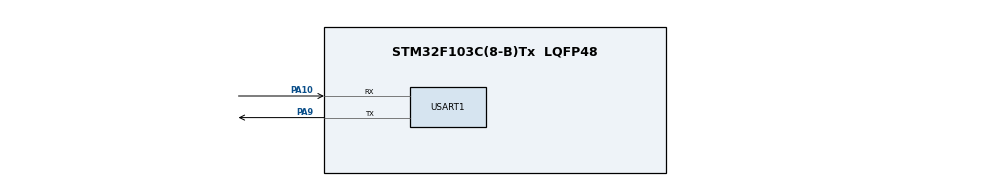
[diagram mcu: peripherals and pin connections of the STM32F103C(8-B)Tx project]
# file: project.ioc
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FREERTOS.Mutexes01=myMutex01,Dynamic,NULL,Available
FREERTOS.Tasks01=FastTask,24,128,StartFastTask,Default,NULL,Dynamic,NULL,NULL;MedTask,16,128,StartMedTask,Default,NULL,Dynamic,NULL,NULL;SlowTask,8,128,StartSlowTask,Default,NULL,Dynamic,NULL,NULL
FREERTOS.configTOTAL_HEAP_SIZE=8192
Mcu.Family=STM32F1
Mcu.Name=STM32F103C(8-B)Tx
Mcu.Package=LQFP48
NVIC.PriorityGroup=NVIC_PRIORITYGROUP_4
PA10.Mode=Asynchronous
PA10.Signal=USART1_RX
PA9.Mode=Asynchronous
PA9.Signal=USART1_TX
ProjectManager.HeapSize=0x200
ProjectManager.StackSize=0x400
ProjectManager.TargetToolchain=STM32CubeIDE
RCC.APB1Freq_Value=8000000
RCC.APB2Freq_Value=8000000
USART1.VirtualMode=VM_ASYNC
VP_FREERTOS_VS_CMSIS_V2.Mode=CMSIS_V2
VP_SYS_VS_ND.Mode=No_Debug
board=custom

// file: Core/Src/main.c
/* USER CODE BEGIN Header */
/**
  ******************************************************************************
  * @file           : main.c
  * @brief          : Main program body
  ******************************************************************************
  * @attention
  *
  * Copyright (c) 2026 STMicroelectronics.
  * All rights reserved.
  *
  * This software is licensed under terms that can be found in the LICENSE file
  * in the root directory of this software component.
  * If no LICENSE file comes with this software, it is provided AS-IS.
  *
  ******************************************************************************
  */
/* USER CODE END Header */
#include "main.h"
#include "cmsis_os.h"

/* USER CODE BEGIN Includes */
#include <stdio.h>      // vsnprintf
#include <stdarg.h>     // va_list, va_start, va_end
#include <string.h>     // strlen
/* USER CODE END Includes */

/* USER CODE BEGIN PD */
#define USE_MUTEX      1
#define LOG_BUF_SIZE   256
/* USER CODE END PD */

UART_HandleTypeDef huart1;

/* Definitions for FastTask */
osThreadId_t FastTaskHandle;
const osThreadAttr_t FastTask_attributes = {
  .name = "FastTask",
  .stack_size = 128 * 4,
  .priority = (osPriority_t) osPriorityNormal,
};
/* Definitions for MedTask */
osThreadId_t MedTaskHandle;
const osThreadAttr_t MedTask_attributes = {
  .name = "MedTask",
  .stack_size = 128 * 4,
  .priority = (osPriority_t) osPriorityBelowNormal,
};
/* Definitions for SlowTask */
osThreadId_t SlowTaskHandle;
const osThreadAttr_t SlowTask_attributes = {
  .name = "SlowTask",
  .stack_size = 128 * 4,
  .priority = (osPriority_t) osPriorityLow,
};
/* Definitions for myMutex01 */
osMutexId_t myMutex01Handle;
const osMutexAttr_t myMutex01_attributes = {
  .name = "myMutex01"
};

void SystemClock_Config(void);
static void MX_GPIO_Init(void);
static void MX_USART1_UART_Init(void);
void StartFastTask(void *argument);
void StartMedTask(void *argument);
void StartSlowTask(void *argument);

int main(void)
{

  /* MCU Configuration--------------------------------------------------------*/

  /* Reset of all peripherals, Initializes the Flash interface and the Systick. */
  HAL_Init();

  /* Configure the system clock */
  SystemClock_Config();

  /* Initialize all configured peripherals */
  MX_GPIO_Init();
  MX_USART1_UART_Init();
  /* USER CODE BEGIN 2 */
  {
      const char *banner =
#if USE_MUTEX
          "\r\n=== UART MUTEX DEMO — MUTEX ON  ===\r\n\r\n";
#else
          "\r\n=== UART MUTEX DEMO — MUTEX OFF (expect garbage) ===\r\n\r\n";
#endif
      HAL_UART_Transmit(&huart1, (uint8_t *)banner, strlen(banner), 200);
  }

  /* USER CODE END 2 */

  /* Init scheduler */
  osKernelInitialize();
  /* Create the mutex(es) */
  /* creation of myMutex01 */
  myMutex01Handle = osMutexNew(&myMutex01_attributes);

  /* Create the thread(s) */
  /* creation of FastTask */
  FastTaskHandle = osThreadNew(StartFastTask, NULL, &FastTask_attributes);

  /* creation of MedTask */
  MedTaskHandle = osThreadNew(StartMedTask, NULL, &MedTask_attributes);

  /* creation of SlowTask */
  SlowTaskHandle = osThreadNew(StartSlowTask, NULL, &SlowTask_attributes);

  /* USER CODE BEGIN RTOS_EVENTS */
  if (FastTaskHandle == NULL)
      HAL_UART_Transmit(&huart1, (uint8_t *)"FAST FAIL\r\n", 11, 100);
  else
      HAL_UART_Transmit(&huart1, (uint8_t *)"FAST OK\r\n", 9, 100);

  if (MedTaskHandle == NULL)
      HAL_UART_Transmit(&huart1, (uint8_t *)"MED FAIL\r\n", 11, 100);
  else
      HAL_UART_Transmit(&huart1, (uint8_t *)"MED OK\r\n", 9, 100);

  if (SlowTaskHandle == NULL)
      HAL_UART_Transmit(&huart1, (uint8_t *)"Slow FAIL\r\n", 11, 100);
  else
      HAL_UART_Transmit(&huart1, (uint8_t *)"Slow OK\r\n", 9, 100);
  /* add events, ... */
  /* USER CODE END RTOS_EVENTS */

  /* Start scheduler */
  osKernelStart();

  /* We should never get here as control is now taken by the scheduler */

  /* Infinite loop */
  while (1)
  {

  }
}

void SystemClock_Config(void)
{
  RCC_OscInitTypeDef RCC_OscInitStruct = {0};
  RCC_ClkInitTypeDef RCC_ClkInitStruct = {0};

  /** Initializes the RCC Oscillators according to the specified parameters
  * in the RCC_OscInitTypeDef structure.
  */
  RCC_OscInitStruct.OscillatorType = RCC_OSCILLATORTYPE_HSI;
  RCC_OscInitStruct.HSIState = RCC_HSI_ON;
  RCC_OscInitStruct.HSICalibrationValue = RCC_HSICALIBRATION_DEFAULT;
  RCC_OscInitStruct.PLL.PLLState = RCC_PLL_NONE;
  if (HAL_RCC_OscConfig(&RCC_OscInitStruct) != HAL_OK)
  {
    Error_Handler();
  }

  /** Initializes the CPU, AHB and APB buses clocks
  */
  RCC_ClkInitStruct.ClockType = RCC_CLOCKTYPE_HCLK|RCC_CLOCKTYPE_SYSCLK
                              |RCC_CLOCKTYPE_PCLK1|RCC_CLOCKTYPE_PCLK2;
  RCC_ClkInitStruct.SYSCLKSource = RCC_SYSCLKSOURCE_HSI;
  RCC_ClkInitStruct.AHBCLKDivider = RCC_SYSCLK_DIV1;
  RCC_ClkInitStruct.APB1CLKDivider = RCC_HCLK_DIV1;
  RCC_ClkInitStruct.APB2CLKDivider = RCC_HCLK_DIV1;

  if (HAL_RCC_ClockConfig(&RCC_ClkInitStruct, FLASH_LATENCY_0) != HAL_OK)
  {
    Error_Handler();
  }
}

static void MX_USART1_UART_Init(void)
{

  huart1.Instance = USART1;
  huart1.Init.BaudRate = 115200;
  huart1.Init.WordLength = UART_WORDLENGTH_8B;
  huart1.Init.StopBits = UART_STOPBITS_1;
  huart1.Init.Parity = UART_PARITY_NONE;
  huart1.Init.Mode = UART_MODE_TX_RX;
  huart1.Init.HwFlowCtl = UART_HWCONTROL_NONE;
  huart1.Init.OverSampling = UART_OVERSAMPLING_16;
  if (HAL_UART_Init(&huart1) != HAL_OK)
  {
    Error_Handler();
  }

}

static void MX_GPIO_Init(void)
{

  /* GPIO Ports Clock Enable */
  __HAL_RCC_GPIOA_CLK_ENABLE();

}

void StartFastTask(void *argument)
{
  /* USER CODE BEGIN 5 */
  /* Infinite loop */
	(void)argument;

	for(;;){
        HAL_UART_Transmit(&huart1, (uint8_t*)"High task waiting for mutex...\r\n",
                          33, HAL_MAX_DELAY);

        // Take mutex (blocks if held by Low task)
        osMutexAcquire(myMutex01Handle, osWaitForever);

        HAL_UART_Transmit(&huart1, (uint8_t*)"High task got mutex!\r\n", 24, HAL_MAX_DELAY);

        osMutexRelease(myMutex01Handle); // Release mutex
        osDelay(200);
	}
  /* USER CODE END 5 */
}

void StartMedTask(void *argument)
{
  /* USER CODE BEGIN StartMedTask */

  (void)argument;

  /* Infinite loop */
  for(;;)
  {

      HAL_UART_Transmit(&huart1, (uint8_t*)"Med task running\r\n", 18, HAL_MAX_DELAY);

      // Busy loop to simulate CPU work
      for (volatile int i = 0; i < 1000000; i++);

      osDelay(100); // Slight delay

  }
  /* USER CODE END StartMedTask */
}

void StartSlowTask(void *argument)
{
  /* USER CODE BEGIN StartSlowTask */
  (void)argument;

  /* Infinite loop */
  for(;;)
  {
      osMutexAcquire(myMutex01Handle, osWaitForever);

      HAL_UART_Transmit(&huart1, (uint8_t*)"Low task running (holding mutex)\r\n",
                        33, HAL_MAX_DELAY);

      // Simulate long work while holding mutex
      osDelay(500);  // Low task busy

      osMutexRelease(myMutex01Handle); // Release mutex
      osDelay(100);                     // Rest a bit
  }
  /* USER CODE END StartSlowTask */
}

void Error_Handler(void)
{
  __disable_irq();
  while (1)
  {
  }
}
